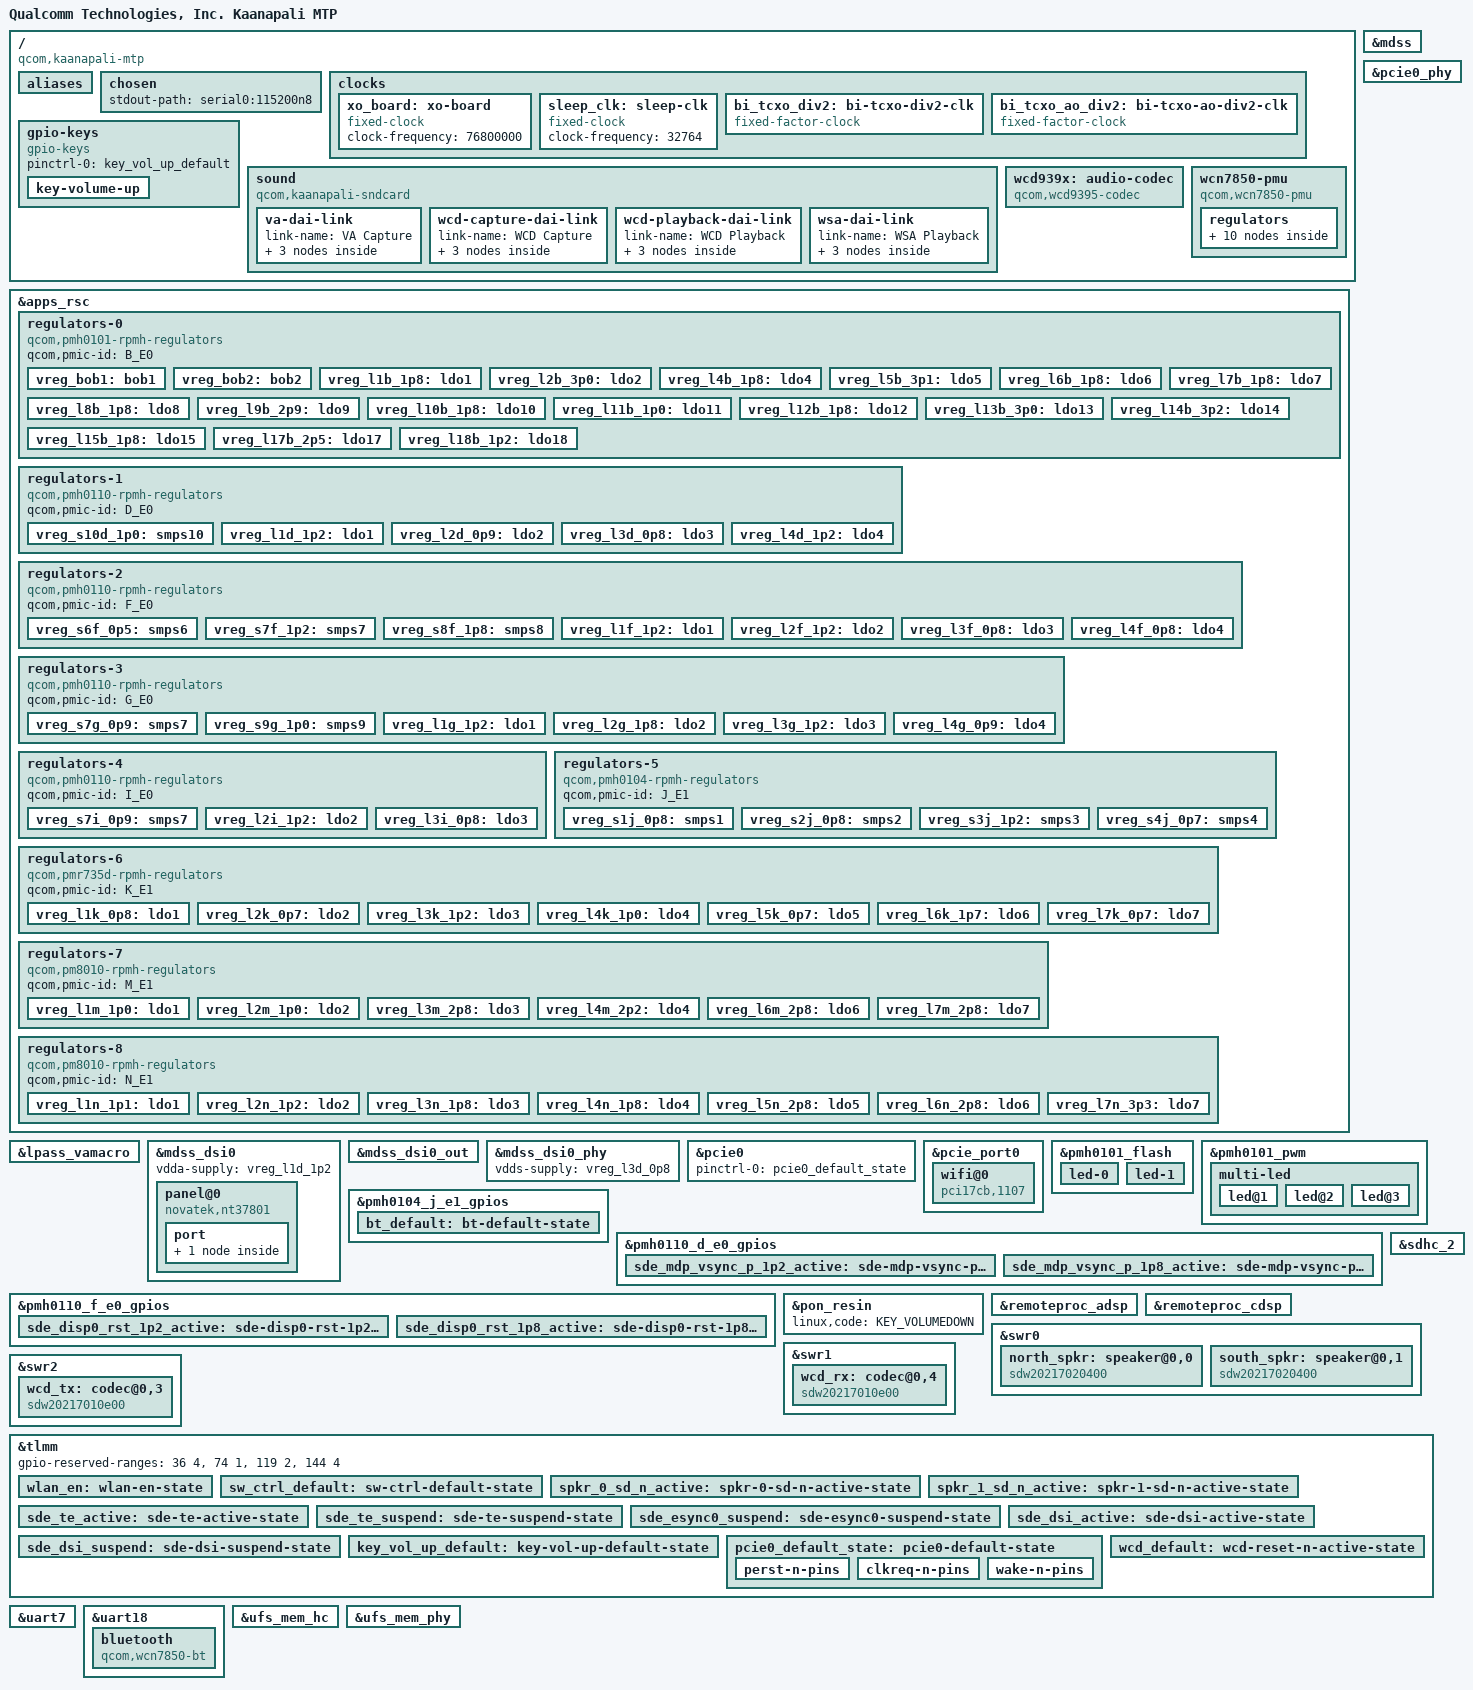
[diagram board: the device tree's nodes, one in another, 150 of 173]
// SPDX-License-Identifier: BSD-3-Clause
/*
 * Copyright (c) Qualcomm Technologies, Inc. and/or its subsidiaries.
 */

/dts-v1/;

#include <dt-bindings/gpio/gpio.h>
#include <dt-bindings/input/linux-event-codes.h>
#include <dt-bindings/leds/common.h>
#include <dt-bindings/regulator/qcom,rpmh-regulator.h>
#include "kaanapali.dtsi"

#include "pm8010-kaanapali.dtsi"     /* SPMI1: SID-12/13   */
#include "pmd8028-kaanapali.dtsi"    /* SPMI1: SID-4       */
#include "pmh0101.dtsi"              /* SPMI0: SID-1       */
#include "pmh0104-kaanapali.dtsi"    /* SPMI1: SID-9       */
#include "pmh0110-kaanapali.dtsi"    /* SPMI0: SID-3/5/6/8 */
#include "pmih0108-kaanapali.dtsi"   /* SPMI1: SID-7       */
#include "pmk8850.dtsi"              /* SPMI0: SID-0       */
#include "pmr735d-kaanapali.dtsi"    /* SPMI1: SID-10      */

/ {
	model = "Qualcomm Technologies, Inc. Kaanapali MTP";
	compatible = "qcom,kaanapali-mtp", "qcom,kaanapali";
	chassis-type = "handset";

	aliases {
		serial0 = &uart7;
		serial1 = &uart18;
	};

	chosen {
		stdout-path = "serial0:115200n8";
	};

	clocks {
		xo_board: xo-board {
			compatible = "fixed-clock";
			clock-frequency = <76800000>;
			#clock-cells = <0>;
		};

		sleep_clk: sleep-clk {
			compatible = "fixed-clock";
			clock-frequency = <32764>;
			#clock-cells = <0>;
		};

		bi_tcxo_div2: bi-tcxo-div2-clk {
			compatible = "fixed-factor-clock";
			#clock-cells = <0>;

			clocks = <&rpmhcc RPMH_CXO_CLK>;
			clock-mult = <1>;
			clock-div = <2>;
		};

		bi_tcxo_ao_div2: bi-tcxo-ao-div2-clk {
			compatible = "fixed-factor-clock";
			#clock-cells = <0>;

			clocks = <&rpmhcc RPMH_CXO_CLK_A>;
			clock-mult = <1>;
			clock-div = <2>;
		};
	};

	gpio-keys {
		compatible = "gpio-keys";

		pinctrl-0 = <&key_vol_up_default>;
		pinctrl-names = "default";

		key-volume-up {
			label = "Volume Up";
			linux,code = <KEY_VOLUMEUP>;
			gpios = <&tlmm 101 GPIO_ACTIVE_LOW>;
			debounce-interval = <15>;
			linux,can-disable;
			wakeup-source;
		};
	};

	sound {
		compatible = "qcom,kaanapali-sndcard", "qcom,sm8450-sndcard";
		model = "Kaanapali-MTP";

		audio-routing = "SpkrLeft IN", "WSA_SPK1 OUT",
				"SpkrRight IN", "WSA_SPK2 OUT",
				"IN1_HPHL", "HPHL_OUT",
				"IN2_HPHR", "HPHR_OUT",
				"AMIC2", "MIC BIAS2",
				"VA DMIC0", "MIC BIAS1",
				"VA DMIC1", "MIC BIAS1",
				"VA DMIC2", "MIC BIAS3",
				"VA DMIC3", "MIC BIAS3",
				"TX SWR_INPUT1", "ADC2_OUTPUT";

		va-dai-link {
			link-name = "VA Capture";

			codec {
				sound-dai = <&lpass_vamacro 0>;
			};

			cpu {
				sound-dai = <&q6apmbedai VA_CODEC_DMA_TX_0>;
			};

			platform {
				sound-dai = <&q6apm>;
			};
		};

		wcd-capture-dai-link {
			link-name = "WCD Capture";

			codec {
				sound-dai = <&wcd939x 1>, <&swr2 0>, <&lpass_txmacro 0>;
			};

			cpu {
				sound-dai = <&q6apmbedai TX_CODEC_DMA_TX_3>;
			};

			platform {
				sound-dai = <&q6apm>;
			};
		};

		wcd-playback-dai-link {
			link-name = "WCD Playback";

			codec {
				sound-dai = <&wcd939x 0>, <&swr1 0>, <&lpass_rxmacro 0>;
			};

			cpu {
				sound-dai = <&q6apmbedai RX_CODEC_DMA_RX_0>;
			};

			platform {
				sound-dai = <&q6apm>;
			};
		};

		wsa-dai-link {
			link-name = "WSA Playback";

			codec {
				sound-dai = <&north_spkr>, <&south_spkr>, <&swr0 0>,
					    <&lpass_wsamacro 0>;
			};

			cpu {
				sound-dai = <&q6apmbedai WSA_CODEC_DMA_RX_0>;
			};

			platform {
				sound-dai = <&q6apm>;
			};
		};
	};

	wcd939x: audio-codec {
		compatible = "qcom,wcd9395-codec", "qcom,wcd9390-codec";

		pinctrl-0 = <&wcd_default>;
		pinctrl-names = "default";

		qcom,micbias1-microvolt = <1800000>;
		qcom,micbias2-microvolt = <1800000>;
		qcom,micbias3-microvolt = <1800000>;
		qcom,micbias4-microvolt = <1800000>;
		qcom,mbhc-buttons-vthreshold-microvolt = <75000 150000 237000 500000
							  500000 500000 500000 500000>;
		qcom,mbhc-headset-vthreshold-microvolt = <1700000>;
		qcom,mbhc-headphone-vthreshold-microvolt = <50000>;
		qcom,rx-device = <&wcd_rx>;
		qcom,tx-device = <&wcd_tx>;

		reset-gpios = <&tlmm 161 GPIO_ACTIVE_LOW>;

		vdd-buck-supply = <&vreg_l15b_1p8>;
		vdd-rxtx-supply = <&vreg_l15b_1p8>;
		vdd-io-supply = <&vreg_l15b_1p8>;
		vdd-mic-bias-supply = <&vreg_bob1>;
		vdd-px-supply = <&vreg_l1g_1p2>;

		#sound-dai-cells = <1>;
	};

	wcn7850-pmu {
		compatible = "qcom,wcn7850-pmu";

		pinctrl-0 = <&bt_default>, <&sw_ctrl_default>, <&wlan_en>;
		pinctrl-names = "default";

		bt-enable-gpios = <&pmh0104_j_e1_gpios 5 GPIO_ACTIVE_HIGH>;
		wlan-enable-gpios = <&tlmm 16 GPIO_ACTIVE_HIGH>;

		vdd-supply = <&vreg_s2j_0p8>;
		vddio-supply = <&vreg_l2g_1p8>;
		vddio1p2-supply = <&vreg_l3g_1p2>;
		vddaon-supply = <&vreg_s7g_0p9>;
		vdddig-supply = <&vreg_s1j_0p8>;
		vddrfa1p2-supply = <&vreg_s7f_1p2>;
		vddrfa1p8-supply = <&vreg_s8f_1p8>;

		clocks = <&rpmhcc RPMH_RF_CLK1>;

		regulators {
			vreg_pmu_rfa_cmn: ldo0 {
				regulator-name = "vreg_pmu_rfa_cmn";
			};

			vreg_pmu_aon_0p59: ldo1 {
				regulator-name = "vreg_pmu_aon_0p59";
			};

			vreg_pmu_wlcx_0p8: ldo2 {
				regulator-name = "vreg_pmu_wlcx_0p8";
			};

			vreg_pmu_wlmx_0p85: ldo3 {
				regulator-name = "vreg_pmu_wlmx_0p85";
			};

			vreg_pmu_btcmx_0p85: ldo4 {
				regulator-name = "vreg_pmu_btcmx_0p85";
			};

			vreg_pmu_rfa_0p8: ldo5 {
				regulator-name = "vreg_pmu_rfa_0p8";
			};

			vreg_pmu_rfa_1p2: ldo6 {
				regulator-name = "vreg_pmu_rfa_1p2";
			};

			vreg_pmu_rfa_1p8: ldo7 {
				regulator-name = "vreg_pmu_rfa_1p8";
			};

			vreg_pmu_pcie_0p9: ldo8 {
				regulator-name = "vreg_pmu_pcie_0p9";
			};

			vreg_pmu_pcie_1p8: ldo9 {
				regulator-name = "vreg_pmu_pcie_1p8";
			};
		};
	};
};

&apps_rsc {
	regulators-0 {
		compatible = "qcom,pmh0101-rpmh-regulators";
		qcom,pmic-id = "B_E0";

		vreg_bob1: bob1 {
			regulator-name = "vreg_bob1";
			regulator-min-microvolt = <3008000>;
			regulator-max-microvolt = <4000000>;
			regulator-initial-mode = <RPMH_REGULATOR_MODE_HPM>;
		};

		vreg_bob2: bob2 {
			regulator-name = "vreg_bob2";
			regulator-min-microvolt = <2704000>;
			regulator-max-microvolt = <3552000>;
			regulator-initial-mode = <RPMH_REGULATOR_MODE_HPM>;
		};

		vreg_l1b_1p8: ldo1 {
			regulator-name = "vreg_l1b_1p8";
			regulator-min-microvolt = <1800000>;
			regulator-max-microvolt = <1800000>;
			regulator-initial-mode = <RPMH_REGULATOR_MODE_AUTO>;
			regulator-allow-set-load;
			regulator-allowed-modes = <RPMH_REGULATOR_MODE_LPM
						   RPMH_REGULATOR_MODE_AUTO>;
		};

		vreg_l2b_3p0: ldo2 {
			regulator-name = "vreg_l2b_3p0";
			regulator-min-microvolt = <3008000>;
			regulator-max-microvolt = <3048000>;
			regulator-initial-mode = <RPMH_REGULATOR_MODE_AUTO>;
			regulator-allow-set-load;
			regulator-allowed-modes = <RPMH_REGULATOR_MODE_LPM
						   RPMH_REGULATOR_MODE_AUTO>;
		};

		vreg_l4b_1p8: ldo4 {
			regulator-name = "vreg_l4b_1p8";
			regulator-min-microvolt = <1800000>;
			regulator-max-microvolt = <1800000>;
			regulator-initial-mode = <RPMH_REGULATOR_MODE_AUTO>;
			regulator-allow-set-load;
			regulator-allowed-modes = <RPMH_REGULATOR_MODE_LPM
						   RPMH_REGULATOR_MODE_AUTO>;
		};

		vreg_l5b_3p1: ldo5 {
			regulator-name = "vreg_l5b_3p1";
			regulator-min-microvolt = <3100000>;
			regulator-max-microvolt = <3148000>;
			regulator-initial-mode = <RPMH_REGULATOR_MODE_AUTO>;
			regulator-allow-set-load;
			regulator-allowed-modes = <RPMH_REGULATOR_MODE_LPM
						   RPMH_REGULATOR_MODE_AUTO>;
		};

		vreg_l6b_1p8: ldo6 {
			regulator-name = "vreg_l6b_1p8";
			regulator-min-microvolt = <1800000>;
			regulator-max-microvolt = <3008000>;
			regulator-initial-mode = <RPMH_REGULATOR_MODE_AUTO>;
			regulator-allow-set-load;
			regulator-allowed-modes = <RPMH_REGULATOR_MODE_LPM
						   RPMH_REGULATOR_MODE_AUTO>;
		};

		vreg_l7b_1p8: ldo7 {
			regulator-name = "vreg_l7b_1p8";
			regulator-min-microvolt = <1800000>;
			regulator-max-microvolt = <3008000>;
			regulator-initial-mode = <RPMH_REGULATOR_MODE_AUTO>;
			regulator-allow-set-load;
			regulator-allowed-modes = <RPMH_REGULATOR_MODE_LPM
						   RPMH_REGULATOR_MODE_AUTO>;
		};

		vreg_l8b_1p8: ldo8 {
			regulator-name = "vreg_l8b_1p8";
			regulator-min-microvolt = <1800000>;
			regulator-max-microvolt = <3008000>;
			regulator-initial-mode = <RPMH_REGULATOR_MODE_AUTO>;
			regulator-allow-set-load;
			regulator-allowed-modes = <RPMH_REGULATOR_MODE_LPM
						   RPMH_REGULATOR_MODE_AUTO>;
		};

		vreg_l9b_2p9: ldo9 {
			regulator-name = "vreg_l9b_2p9";
			regulator-min-microvolt = <2960000>;
			regulator-max-microvolt = <3008000>;
			regulator-initial-mode = <RPMH_REGULATOR_MODE_HPM>;
			regulator-allow-set-load;
			regulator-allowed-modes = <RPMH_REGULATOR_MODE_LPM
						   RPMH_REGULATOR_MODE_HPM>;
		};

		vreg_l10b_1p8: ldo10 {
			regulator-name = "vreg_l10b_1p8";
			regulator-min-microvolt = <1800000>;
			regulator-max-microvolt = <1800000>;
			regulator-initial-mode = <RPMH_REGULATOR_MODE_AUTO>;
			regulator-allow-set-load;
			regulator-allowed-modes = <RPMH_REGULATOR_MODE_LPM
						   RPMH_REGULATOR_MODE_AUTO>;
		};

		vreg_l11b_1p0: ldo11 {
			regulator-name = "vreg_l11b_1p0";
			regulator-min-microvolt = <1000000>;
			regulator-max-microvolt = <1292000>;
			regulator-initial-mode = <RPMH_REGULATOR_MODE_AUTO>;
			regulator-allow-set-load;
			regulator-allowed-modes = <RPMH_REGULATOR_MODE_LPM
						   RPMH_REGULATOR_MODE_AUTO>;
		};

		vreg_l12b_1p8: ldo12 {
			regulator-name = "vreg_l12b_1p8";
			regulator-min-microvolt = <1650000>;
			regulator-max-microvolt = <1800000>;
			regulator-initial-mode = <RPMH_REGULATOR_MODE_AUTO>;
			regulator-allow-set-load;
			regulator-allowed-modes = <RPMH_REGULATOR_MODE_LPM
						   RPMH_REGULATOR_MODE_AUTO>;
		};

		vreg_l13b_3p0: ldo13 {
			regulator-name = "vreg_l13b_3p0";
			regulator-min-microvolt = <3000000>;
			regulator-max-microvolt = <3000000>;
			regulator-initial-mode = <RPMH_REGULATOR_MODE_AUTO>;
			regulator-allow-set-load;
			regulator-allowed-modes = <RPMH_REGULATOR_MODE_LPM
						   RPMH_REGULATOR_MODE_AUTO>;
		};

		vreg_l14b_3p2: ldo14 {
			regulator-name = "vreg_l14b_3p2";
			regulator-min-microvolt = <3200000>;
			regulator-max-microvolt = <3200000>;
			regulator-initial-mode = <RPMH_REGULATOR_MODE_AUTO>;
			regulator-allow-set-load;
			regulator-allowed-modes = <RPMH_REGULATOR_MODE_LPM
						   RPMH_REGULATOR_MODE_AUTO>;
		};

		vreg_l15b_1p8: ldo15 {
			regulator-name = "vreg_l15b_1p8";
			regulator-min-microvolt = <1800000>;
			regulator-max-microvolt = <1800000>;
			regulator-initial-mode = <RPMH_REGULATOR_MODE_AUTO>;
			regulator-allow-set-load;
			regulator-allowed-modes = <RPMH_REGULATOR_MODE_LPM
						   RPMH_REGULATOR_MODE_AUTO>;
		};

		vreg_l17b_2p5: ldo17 {
			regulator-name = "vreg_l17b_2p5";
			regulator-min-microvolt = <2504000>;
			regulator-max-microvolt = <2504000>;
			regulator-initial-mode = <RPMH_REGULATOR_MODE_HPM>;
			regulator-allow-set-load;
			regulator-allowed-modes = <RPMH_REGULATOR_MODE_LPM
						   RPMH_REGULATOR_MODE_HPM>;
		};

		vreg_l18b_1p2: ldo18 {
			regulator-name = "vreg_l18b_1p2";
			regulator-min-microvolt = <1200000>;
			regulator-max-microvolt = <1200000>;
			regulator-initial-mode = <RPMH_REGULATOR_MODE_AUTO>;
			regulator-allow-set-load;
			regulator-allowed-modes = <RPMH_REGULATOR_MODE_LPM
						   RPMH_REGULATOR_MODE_AUTO>;
		};
	};

	regulators-1 {
		compatible = "qcom,pmh0110-rpmh-regulators";
		qcom,pmic-id = "D_E0";

		vreg_s10d_1p0: smps10 {
			regulator-name = "vreg_s10d_1p0";
			regulator-min-microvolt = <1000000>;
			regulator-max-microvolt = <1100000>;
			regulator-initial-mode = <RPMH_REGULATOR_MODE_HPM>;
		};

		vreg_l1d_1p2: ldo1 {
			regulator-name = "vreg_l1d_1p2";
			regulator-min-microvolt = <1200000>;
			regulator-max-microvolt = <1256000>;
			regulator-initial-mode = <RPMH_REGULATOR_MODE_AUTO>;
			regulator-allow-set-load;
			regulator-allowed-modes = <RPMH_REGULATOR_MODE_LPM
						   RPMH_REGULATOR_MODE_AUTO>;
		};

		vreg_l2d_0p9: ldo2 {
			regulator-name = "vreg_l2d_0p9";
			regulator-min-microvolt = <912000>;
			regulator-max-microvolt = <958000>;
			regulator-initial-mode = <RPMH_REGULATOR_MODE_AUTO>;
			regulator-allow-set-load;
			regulator-allowed-modes = <RPMH_REGULATOR_MODE_LPM
						   RPMH_REGULATOR_MODE_AUTO>;
		};

		vreg_l3d_0p8: ldo3 {
			regulator-name = "vreg_l3d_0p8";
			regulator-min-microvolt = <880000>;
			regulator-max-microvolt = <880000>;
			regulator-initial-mode = <RPMH_REGULATOR_MODE_AUTO>;
			regulator-allow-set-load;
			regulator-allowed-modes = <RPMH_REGULATOR_MODE_LPM
						   RPMH_REGULATOR_MODE_AUTO>;
		};

		vreg_l4d_1p2: ldo4 {
			regulator-name = "vreg_l4d_1p2";
			regulator-min-microvolt = <1200000>;
			regulator-max-microvolt = <1200000>;
			regulator-initial-mode = <RPMH_REGULATOR_MODE_AUTO>;
			regulator-allow-set-load;
			regulator-allowed-modes = <RPMH_REGULATOR_MODE_LPM
						   RPMH_REGULATOR_MODE_AUTO>;
		};
	};

	regulators-2 {
		compatible = "qcom,pmh0110-rpmh-regulators";
		qcom,pmic-id = "F_E0";

		vreg_s6f_0p5: smps6 {
			regulator-name = "vreg_s6f_0p5";
			regulator-min-microvolt = <300000>;
			regulator-max-microvolt = <570000>;
			regulator-initial-mode = <RPMH_REGULATOR_MODE_HPM>;
		};

		vreg_s7f_1p2: smps7 {
			regulator-name = "vreg_s7f_1p2";
			regulator-min-microvolt = <1224000>;
			regulator-max-microvolt = <1372000>;
			regulator-initial-mode = <RPMH_REGULATOR_MODE_HPM>;
		};

		vreg_s8f_1p8: smps8 {
			regulator-name = "vreg_s8f_1p8";
			regulator-min-microvolt = <1800000>;
			regulator-max-microvolt = <2000000>;
			regulator-initial-mode = <RPMH_REGULATOR_MODE_HPM>;
		};

		vreg_l1f_1p2: ldo1 {
			regulator-name = "vreg_l1f_1p2";
			regulator-min-microvolt = <1200000>;
			regulator-max-microvolt = <1200000>;
			regulator-initial-mode = <RPMH_REGULATOR_MODE_AUTO>;
			regulator-allow-set-load;
			regulator-allowed-modes = <RPMH_REGULATOR_MODE_LPM
						   RPMH_REGULATOR_MODE_AUTO>;
		};

		vreg_l2f_1p2: ldo2 {
			regulator-name = "vreg_l2f_1p2";
			regulator-min-microvolt = <1200000>;
			regulator-max-microvolt = <1200000>;
			regulator-initial-mode = <RPMH_REGULATOR_MODE_AUTO>;
			regulator-allow-set-load;
			regulator-allowed-modes = <RPMH_REGULATOR_MODE_LPM
						   RPMH_REGULATOR_MODE_AUTO>;
		};

		vreg_l3f_0p8: ldo3 {
			regulator-name = "vreg_l3f_0p8";
			regulator-min-microvolt = <880000>;
			regulator-max-microvolt = <936000>;
			regulator-initial-mode = <RPMH_REGULATOR_MODE_AUTO>;
			regulator-allow-set-load;
			regulator-allowed-modes = <RPMH_REGULATOR_MODE_LPM
						   RPMH_REGULATOR_MODE_AUTO>;
		};

		vreg_l4f_0p8: ldo4 {
			regulator-name = "vreg_l4f_0p8";
			regulator-min-microvolt = <880000>;
			regulator-max-microvolt = <912000>;
			regulator-initial-mode = <RPMH_REGULATOR_MODE_AUTO>;
			regulator-allow-set-load;
			regulator-allowed-modes = <RPMH_REGULATOR_MODE_LPM
						   RPMH_REGULATOR_MODE_AUTO>;
		};
	};

	regulators-3 {
		compatible = "qcom,pmh0110-rpmh-regulators";
		qcom,pmic-id = "G_E0";

		vreg_s7g_0p9: smps7 {
			regulator-name = "vreg_s7g_0p9";
			regulator-min-microvolt = <880000>;
			regulator-max-microvolt = <1100000>;
			regulator-initial-mode = <RPMH_REGULATOR_MODE_HPM>;
		};

		vreg_s9g_1p0: smps9 {
			regulator-name = "vreg_s9g_1p0";
			regulator-min-microvolt = <1000000>;
			regulator-max-microvolt = <1100000>;
			regulator-initial-mode = <RPMH_REGULATOR_MODE_HPM>;
		};

		vreg_l1g_1p2: ldo1 {
			regulator-name = "vreg_l1g_1p2";
			regulator-min-microvolt = <1200000>;
			regulator-max-microvolt = <1200000>;
			regulator-initial-mode = <RPMH_REGULATOR_MODE_AUTO>;
			regulator-allow-set-load;
			regulator-allowed-modes = <RPMH_REGULATOR_MODE_LPM
						   RPMH_REGULATOR_MODE_AUTO>;
		};

		vreg_l2g_1p8: ldo2 {
			regulator-name = "vreg_l2g_1p8";
			regulator-min-microvolt = <1800000>;
			regulator-max-microvolt = <1800000>;
			regulator-initial-mode = <RPMH_REGULATOR_MODE_AUTO>;
			regulator-allow-set-load;
			regulator-allowed-modes = <RPMH_REGULATOR_MODE_LPM
						   RPMH_REGULATOR_MODE_AUTO>;
		};

		vreg_l3g_1p2: ldo3 {
			regulator-name = "vreg_l3g_1p2";
			regulator-min-microvolt = <1200000>;
			regulator-max-microvolt = <1200000>;
			regulator-initial-mode = <RPMH_REGULATOR_MODE_AUTO>;
			regulator-allow-set-load;
			regulator-allowed-modes = <RPMH_REGULATOR_MODE_LPM
						   RPMH_REGULATOR_MODE_AUTO>;
		};

		vreg_l4g_0p9: ldo4 {
			regulator-name = "vreg_l4g_0p9";
			regulator-min-microvolt = <880000>;
			regulator-max-microvolt = <920000>;
			regulator-initial-mode = <RPMH_REGULATOR_MODE_AUTO>;
			regulator-allow-set-load;
			regulator-allowed-modes = <RPMH_REGULATOR_MODE_LPM
						   RPMH_REGULATOR_MODE_AUTO>;
		};
	};

	regulators-4 {
		compatible = "qcom,pmh0110-rpmh-regulators";
		qcom,pmic-id = "I_E0";

		vreg_s7i_0p9: smps7 {
			regulator-name = "vreg_s7i_0p9";
			regulator-min-microvolt = <900000>;
			regulator-max-microvolt = <972000>;
			regulator-initial-mode = <RPMH_REGULATOR_MODE_HPM>;
		};

		vreg_l2i_1p2: ldo2 {
			regulator-name = "vreg_l2i_1p2";
			regulator-min-microvolt = <1200000>;
			regulator-max-microvolt = <1200000>;
			regulator-initial-mode = <RPMH_REGULATOR_MODE_AUTO>;
			regulator-allow-set-load;
			regulator-allowed-modes = <RPMH_REGULATOR_MODE_LPM
						   RPMH_REGULATOR_MODE_AUTO>;
		};

		vreg_l3i_0p8: ldo3 {
			regulator-name = "vreg_l3i_0p8";
			regulator-min-microvolt = <880000>;
			regulator-max-microvolt = <920000>;
			regulator-initial-mode = <RPMH_REGULATOR_MODE_AUTO>;
			regulator-allow-set-load;
			regulator-allowed-modes = <RPMH_REGULATOR_MODE_LPM
						   RPMH_REGULATOR_MODE_AUTO>;
		};
	};

	regulators-5 {
		compatible = "qcom,pmh0104-rpmh-regulators";
		qcom,pmic-id = "J_E1";

		vreg_s1j_0p8: smps1 {
			regulator-name = "vreg_s1j_0p8";
			regulator-min-microvolt = <400000>;
			regulator-max-microvolt = <1000000>;
			regulator-initial-mode = <RPMH_REGULATOR_MODE_HPM>;
		};

		vreg_s2j_0p8: smps2 {
			regulator-name = "vreg_s2j_0p8";
			regulator-min-microvolt = <500000>;
			regulator-max-microvolt = <1100000>;
			regulator-initial-mode = <RPMH_REGULATOR_MODE_HPM>;
		};

		vreg_s3j_1p2: smps3 {
			regulator-name = "vreg_s3j_1p2";
			regulator-min-microvolt = <1200000>;
			regulator-max-microvolt = <1300000>;
			regulator-initial-mode = <RPMH_REGULATOR_MODE_HPM>;
		};

		vreg_s4j_0p7: smps4 {
			regulator-name = "vreg_s4j_0p7";
			regulator-min-microvolt = <300000>;
			regulator-max-microvolt = <1000000>;
			regulator-initial-mode = <RPMH_REGULATOR_MODE_HPM>;
		};
	};

	regulators-6 {
		compatible = "qcom,pmr735d-rpmh-regulators";
		qcom,pmic-id = "K_E1";

		vreg_l1k_0p8: ldo1 {
			regulator-name = "vreg_l1k_0p8";
			regulator-min-microvolt = <300000>;
			regulator-max-microvolt = <1100000>;
			regulator-initial-mode = <RPMH_REGULATOR_MODE_HPM>;
			regulator-allow-set-load;
			regulator-allowed-modes = <RPMH_REGULATOR_MODE_LPM
						   RPMH_REGULATOR_MODE_HPM>;
		};

		vreg_l2k_0p7: ldo2 {
			regulator-name = "vreg_l2k_0p7";
			regulator-min-microvolt = <700000>;
			regulator-max-microvolt = <1000000>;
			regulator-initial-mode = <RPMH_REGULATOR_MODE_HPM>;
			regulator-allow-set-load;
			regulator-allowed-modes = <RPMH_REGULATOR_MODE_LPM
						   RPMH_REGULATOR_MODE_HPM>;
		};

		vreg_l3k_1p2: ldo3 {
			regulator-name = "vreg_l3k_1p2";
			regulator-min-microvolt = <1200000>;
			regulator-max-microvolt = <1200000>;
			regulator-initial-mode = <RPMH_REGULATOR_MODE_HPM>;
			regulator-allow-set-load;
			regulator-allowed-modes = <RPMH_REGULATOR_MODE_LPM
						   RPMH_REGULATOR_MODE_HPM>;
		};

		vreg_l4k_1p0: ldo4 {
			regulator-name = "vreg_l4k_1p0";
			regulator-min-microvolt = <1000000>;
			regulator-max-microvolt = <1200000>;
			regulator-initial-mode = <RPMH_REGULATOR_MODE_HPM>;
			regulator-allow-set-load;
			regulator-allowed-modes = <RPMH_REGULATOR_MODE_LPM
						   RPMH_REGULATOR_MODE_HPM>;
		};

		vreg_l5k_0p7: ldo5 {
			regulator-name = "vreg_l5k_0p7";
			regulator-min-microvolt = <700000>;
			regulator-max-microvolt = <1000000>;
			regulator-initial-mode = <RPMH_REGULATOR_MODE_HPM>;
			regulator-allow-set-load;
			regulator-allowed-modes = <RPMH_REGULATOR_MODE_LPM
						   RPMH_REGULATOR_MODE_HPM>;
		};

		vreg_l6k_1p7: ldo6 {
			regulator-name = "vreg_l6k_1p7";
			regulator-min-microvolt = <1700000>;
			regulator-max-microvolt = <2000000>;
			regulator-initial-mode = <RPMH_REGULATOR_MODE_HPM>;
			regulator-allow-set-load;
			regulator-allowed-modes = <RPMH_REGULATOR_MODE_LPM
						   RPMH_REGULATOR_MODE_HPM>;
		};

		vreg_l7k_0p7: ldo7 {
			regulator-name = "vreg_l7k_0p7";
			regulator-min-microvolt = <700000>;
			regulator-max-microvolt = <848000>;
			regulator-initial-mode = <RPMH_REGULATOR_MODE_HPM>;
			regulator-allow-set-load;
			regulator-allowed-modes = <RPMH_REGULATOR_MODE_LPM
						   RPMH_REGULATOR_MODE_HPM>;
		};
	};

	regulators-7 {
		compatible = "qcom,pm8010-rpmh-regulators";
		qcom,pmic-id = "M_E1";

		vreg_l1m_1p0: ldo1 {
			regulator-name = "vreg_l1m_1p0";
			regulator-min-microvolt = <1000000>;
			regulator-max-microvolt = <1100000>;
			regulator-initial-mode = <RPMH_REGULATOR_MODE_HPM>;
			regulator-allow-set-load;
			regulator-allowed-modes = <RPMH_REGULATOR_MODE_LPM
						   RPMH_REGULATOR_MODE_HPM>;
		};

		vreg_l2m_1p0: ldo2 {
			regulator-name = "vreg_l2m_1p0";
			regulator-min-microvolt = <1096000>;
			regulator-max-microvolt = <1104000>;
			regulator-initial-mode = <RPMH_REGULATOR_MODE_HPM>;
			regulator-allow-set-load;
			regulator-allowed-modes = <RPMH_REGULATOR_MODE_LPM
						   RPMH_REGULATOR_MODE_HPM>;
		};

		vreg_l3m_2p8: ldo3 {
			regulator-name = "vreg_l3m_2p8";
			regulator-min-microvolt = <2800000>;
			regulator-max-microvolt = <2900000>;
			regulator-initial-mode = <RPMH_REGULATOR_MODE_HPM>;
		};

		vreg_l4m_2p2: ldo4 {
			regulator-name = "vreg_l4m_2p2";
			regulator-min-microvolt = <2200000>;
			regulator-max-microvolt = <2200000>;
			regulator-initial-mode = <RPMH_REGULATOR_MODE_HPM>;
		};

		vreg_l6m_2p8: ldo6 {
			regulator-name = "vreg_l6m_2p8";
			regulator-min-microvolt = <2800000>;
			regulator-max-microvolt = <2800000>;
			regulator-initial-mode = <RPMH_REGULATOR_MODE_HPM>;
		};

		vreg_l7m_2p8: ldo7 {
			regulator-name = "vreg_l7m_2p8";
			regulator-min-microvolt = <2800000>;
			regulator-max-microvolt = <2800000>;
			regulator-initial-mode = <RPMH_REGULATOR_MODE_HPM>;
		};
	};

	regulators-8 {
		compatible = "qcom,pm8010-rpmh-regulators";
		qcom,pmic-id = "N_E1";

		vreg_l1n_1p1: ldo1 {
			regulator-name = "vreg_l1n_1p1";
			regulator-min-microvolt = <1096000>;
			regulator-max-microvolt = <1104000>;
			regulator-initial-mode = <RPMH_REGULATOR_MODE_HPM>;
			regulator-allow-set-load;
			regulator-allowed-modes = <RPMH_REGULATOR_MODE_LPM
						   RPMH_REGULATOR_MODE_HPM>;
		};

		vreg_l2n_1p2: ldo2 {
			regulator-name = "vreg_l2n_1p2";
			regulator-min-microvolt = <1200000>;
			regulator-max-microvolt = <1200000>;
			regulator-initial-mode = <RPMH_REGULATOR_MODE_HPM>;
			regulator-allow-set-load;
			regulator-allowed-modes = <RPMH_REGULATOR_MODE_LPM
						   RPMH_REGULATOR_MODE_HPM>;
		};

		vreg_l3n_1p8: ldo3 {
			regulator-name = "vreg_l3n_1p8";
			regulator-min-microvolt = <1800000>;
			regulator-max-microvolt = <1800000>;
			regulator-initial-mode = <RPMH_REGULATOR_MODE_HPM>;
		};

		vreg_l4n_1p8: ldo4 {
			regulator-name = "vreg_l4n_1p8";
			regulator-min-microvolt = <1800000>;
			regulator-max-microvolt = <1800000>;
			regulator-initial-mode = <RPMH_REGULATOR_MODE_HPM>;
		};

		vreg_l5n_2p8: ldo5 {
			regulator-name = "vreg_l5n_2p8";
			regulator-min-microvolt = <2800000>;
			regulator-max-microvolt = <2800000>;
			regulator-initial-mode = <RPMH_REGULATOR_MODE_HPM>;
		};

		vreg_l6n_2p8: ldo6 {
			regulator-name = "vreg_l6n_2p8";
			regulator-min-microvolt = <2800000>;
			regulator-max-microvolt = <2800000>;
			regulator-initial-mode = <RPMH_REGULATOR_MODE_HPM>;
		};

		vreg_l7n_3p3: ldo7 {
			regulator-name = "vreg_l7n_3p3";
			regulator-min-microvolt = <3304000>;
			regulator-max-microvolt = <3304000>;
			regulator-initial-mode = <RPMH_REGULATOR_MODE_HPM>;
		};
	};
};

&lpass_vamacro {
	pinctrl-0 = <&dmic01_default>, <&dmic23_default>;
	pinctrl-names = "default";

	vdd-micb-supply = <&vreg_l10b_1p8>;
	qcom,dmic-sample-rate = <4800000>;
};

&mdss {
	status = "okay";
};

&mdss_dsi0 {
	vdda-supply = <&vreg_l1d_1p2>;
	status = "okay";

	panel@0 {
		compatible = "novatek,nt37801";
		reg = <0>;

		pinctrl-0 = <&sde_dsi_active &sde_te_active &sde_esync0_suspend
			     &sde_mdp_vsync_p_1p2_active &sde_mdp_vsync_p_1p8_active
			     &sde_disp0_rst_1p2_active &sde_disp0_rst_1p8_active>;
		pinctrl-1 = <&sde_dsi_suspend &sde_te_suspend &sde_esync0_suspend
			     &sde_mdp_vsync_p_1p2_active &sde_mdp_vsync_p_1p8_active
			     &sde_disp0_rst_1p2_active &sde_disp0_rst_1p8_active>;
		pinctrl-names = "default", "sleep";

		vci-supply = <&vreg_l13b_3p0>;
		vdd-supply = <&vreg_l11b_1p0>;
		vddio-supply = <&vreg_l12b_1p8>;

		reset-gpios = <&tlmm 98 GPIO_ACTIVE_LOW>;

		port {
			panel0_in: endpoint {
				remote-endpoint = <&mdss_dsi0_out>;
			};
		};
	};
};

&mdss_dsi0_out {
	remote-endpoint = <&panel0_in>;
	data-lanes = <0 1 2 3>;
};

&mdss_dsi0_phy {
	vdds-supply = <&vreg_l3d_0p8>;

	status = "okay";
};

&pcie0 {
	pinctrl-0 = <&pcie0_default_state>;
	pinctrl-names = "default";

	status = "okay";
};

&pcie0_phy {
	vdda-phy-supply = <&vreg_l3i_0p8>;
	vdda-pll-supply = <&vreg_l1d_1p2>;

	status = "okay";
};

&pcie_port0 {
	wake-gpios = <&tlmm 104 GPIO_ACTIVE_HIGH>;
	reset-gpios = <&tlmm 102 GPIO_ACTIVE_LOW>;

	wifi@0 {
		compatible = "pci17cb,1107";
		reg = <0x10000 0x0 0x0 0x0 0x0>;

		vddrfacmn-supply = <&vreg_pmu_rfa_cmn>;
		vddaon-supply = <&vreg_pmu_aon_0p59>;
		vddwlcx-supply = <&vreg_pmu_wlcx_0p8>;
		vddwlmx-supply = <&vreg_pmu_wlmx_0p85>;
		vddrfa0p8-supply = <&vreg_pmu_rfa_0p8>;
		vddrfa1p2-supply = <&vreg_pmu_rfa_1p2>;
		vddrfa1p8-supply = <&vreg_pmu_rfa_1p8>;
		vddpcie0p9-supply = <&vreg_pmu_pcie_0p9>;
		vddpcie1p8-supply = <&vreg_pmu_pcie_1p8>;
	};
};

&pmh0101_flash {
	status = "okay";

	led-0 {
		function = LED_FUNCTION_FLASH;
		function-enumerator = <0>;
		color = <LED_COLOR_ID_YELLOW>;
		led-sources = <1>, <4>;
		led-max-microamp = <500000>;
		flash-max-microamp = <2000000>;
		flash-max-timeout-us = <1280000>;
	};

	led-1 {
		function = LED_FUNCTION_FLASH;
		function-enumerator = <1>;
		color = <LED_COLOR_ID_WHITE>;
		led-sources = <2>, <3>;
		led-max-microamp = <500000>;
		flash-max-microamp = <2000000>;
		flash-max-timeout-us = <1280000>;
	};
};

&pmh0101_pwm {
	status = "okay";

	multi-led {
		color = <LED_COLOR_ID_RGB>;
		function = LED_FUNCTION_STATUS;

		#address-cells = <1>;
		#size-cells = <0>;

		led@1 {
			reg = <1>;
			color = <LED_COLOR_ID_RED>;
		};

		led@2 {
			reg = <2>;
			color = <LED_COLOR_ID_GREEN>;
		};

		led@3 {
			reg = <3>;
			color = <LED_COLOR_ID_BLUE>;
		};
	};
};

&pmh0104_j_e1_gpios {
	bt_default: bt-default-state {
		pins = "gpio5";
		function = "normal";
		input-disable;
		output-enable;
		output-low;
		bias-disable;
		power-source = <1>;
	};
};

&pmh0110_d_e0_gpios {
	sde_mdp_vsync_p_1p2_active: sde-mdp-vsync-p-1p2-active-state {
		pins = "gpio9";
		function = "paired";
		input-disable;
		output-enable;
		power-source = <2>; /* 1.2v */
	};

	sde_mdp_vsync_p_1p8_active: sde-mdp-vsync-p-1p8-active-state {
		pins = "gpio10";
		function = "paired";
		input-enable;
		output-disable;
		power-source = <1>; /* 1.8v */
	};
};

&pmh0110_f_e0_gpios {
	sde_disp0_rst_1p2_active: sde-disp0-rst-1p2-active-state {
		pins = "gpio9";
		function = "paired";
		input-enable;
		output-disable;
		power-source = <2>; /* 1.2v */
	};

	sde_disp0_rst_1p8_active: sde-disp0-rst-1p8-active-state {
		pins = "gpio10";
		function = "paired";
		input-disable;
		output-enable;
		power-source = <1>; /* 1.8v */
	};
};

&pon_resin {
	linux,code = <KEY_VOLUMEDOWN>;

	status = "okay";
};

&remoteproc_adsp {
	firmware-name = "qcom/kaanapali/adsp.mbn",
			"qcom/kaanapali/adsp_dtb.mbn";

	status = "okay";
};

&remoteproc_cdsp {
	firmware-name = "qcom/kaanapali/cdsp.mbn",
			"qcom/kaanapali/cdsp_dtb.mbn";

	status = "okay";
};

&sdhc_2 {
	cd-gpios = <&tlmm 55 GPIO_ACTIVE_LOW>;

	vmmc-supply = <&vreg_l9b_2p9>;
	vqmmc-supply = <&vreg_l8b_1p8>;

	bus-width = <4>;
	no-sdio;
	no-mmc;

	pinctrl-0 = <&sdc2_default>;
	pinctrl-1 = <&sdc2_sleep>;
	pinctrl-names = "default", "sleep";

	status = "okay";
};

&swr0 {
	status = "okay";

	/* WSA8845, Speaker North */
	north_spkr: speaker@0,0 {
		compatible = "sdw20217020400";
		reg = <0 0>;
		pinctrl-0 = <&spkr_0_sd_n_active>;
		pinctrl-names = "default";
		powerdown-gpios = <&tlmm 76 GPIO_ACTIVE_LOW>;
		#sound-dai-cells = <0>;
		sound-name-prefix = "SpkrLeft";
		vdd-1p8-supply = <&vreg_l15b_1p8>;
		vdd-io-supply = <&vreg_l2i_1p2>;

		/*
		 * WSA8845 Port 1 (DAC)     <=> SWR0 Port 1 (SPKR_L)
		 * WSA8845 Port 2 (COMP)    <=> SWR0 Port 2 (SPKR_L_COMP)
		 * WSA8845 Port 3 (BOOST)   <=> SWR0 Port 3 (SPKR_L_BOOST)
		 * WSA8845 Port 4 (PBR)     <=> SWR0 Port 7 (PBR)
		 * WSA8845 Port 5 (VISENSE) <=> SWR0 Port 10 (SPKR_L_VI)
		 * WSA8845 Port 6 (CPS)     <=> SWR0 Port 13 (CPS)
		 */
		qcom,port-mapping = <1 2 3 7 10 13>;
	};

	/* WSA8845, Speaker South */
	south_spkr: speaker@0,1 {
		compatible = "sdw20217020400";
		reg = <0 1>;
		pinctrl-0 = <&spkr_1_sd_n_active>;
		pinctrl-names = "default";
		powerdown-gpios = <&tlmm 77 GPIO_ACTIVE_LOW>;
		#sound-dai-cells = <0>;
		sound-name-prefix = "SpkrRight";
		vdd-1p8-supply = <&vreg_l15b_1p8>;
		vdd-io-supply = <&vreg_l2i_1p2>;

		/*
		 * WSA8845 Port 1 (DAC)     <=> SWR0 Port 4 (SPKR_R)
		 * WSA8845 Port 2 (COMP)    <=> SWR0 Port 5 (SPKR_R_COMP)
		 * WSA8845 Port 3 (BOOST)   <=> SWR0 Port 6 (SPKR_R_BOOST)
		 * WSA8845 Port 4 (PBR)     <=> SWR0 Port 7 (PBR)
		 * WSA8845 Port 5 (VISENSE) <=> SWR0 Port 11 (SPKR_R_VI)
		 * WSA8845 Port 6 (CPS)     <=> SWR0 Port 13 (CPS)
		 */
		qcom,port-mapping = <4 5 6 7 11 13>;
	};
};

&swr1 {
	status = "okay";

	/* WCD9395 RX */
	wcd_rx: codec@0,4 {
		compatible = "sdw20217010e00";
		reg = <0 4>;

		/*
		 * WCD9395 RX Port 1 (HPH_L/R)      <=> SWR1 Port 1 (HPH_L/R)
		 * WCD9395 RX Port 2 (CLSH)         <=> SWR1 Port 2 (CLSH)
		 * WCD9395 RX Port 3 (COMP_L/R)     <=> SWR1 Port 3 (COMP_L/R)
		 * WCD9395 RX Port 4 (LO)           <=> SWR1 Port 4 (LO)
		 * WCD9395 RX Port 5 (DSD_L/R)      <=> SWR1 Port 5 (DSD_L/R)
		 * WCD9395 RX Port 6 (HIFI_PCM_L/R) <=> SWR1 Port 9 (HIFI_PCM_L/R)
		 */
		qcom,rx-port-mapping = <1 2 3 4 5 9>;
	};
};

&swr2 {
	status = "okay";

	/* WCD9395 TX */
	wcd_tx: codec@0,3 {
		compatible = "sdw20217010e00";
		reg = <0 3>;

		/*
		 * WCD9395 TX Port 1 (ADC1,2,3,4)         <=> SWR2 Port 2 (TX SWR_INPUT 0,1,2,3)
		 * WCD9395 TX Port 2 (ADC3,4 & DMIC0,1)   <=> SWR2 Port 2 (TX SWR_INPUT 0,1,2,3)
		 * WCD9395 TX Port 3 (DMIC0,1,2,3 & MBHC) <=> SWR2 Port 3 (TX SWR_INPUT 4,5,6,7)
		 * WCD9395 TX Port 4 (DMIC4,5,6,7)        <=> SWR2 Port 4 (TX SWR_INPUT 8,9,10,11)
		 */
		qcom,tx-port-mapping = <2 2 3 4>;
	};
};

&tlmm {
	gpio-reserved-ranges = <36 4>, /* NFC eSE SPI */
			       <74 1>, /* eSE */
			       <119 2>, /* SoCCP */
			       <144 4>; /* CXM UART */

	wlan_en: wlan-en-state {
		pins = "gpio16";
		function = "gpio";
		drive-strength = <8>;
		bias-pull-down;
	};

	sw_ctrl_default: sw-ctrl-default-state {
		pins = "gpio18";
		function = "gpio";
		bias-pull-down;
	};

	spkr_0_sd_n_active: spkr-0-sd-n-active-state {
		pins = "gpio76";
		function = "gpio";
		drive-strength = <16>;
		bias-disable;
	};

	spkr_1_sd_n_active: spkr-1-sd-n-active-state {
		pins = "gpio77";
		function = "gpio";
		drive-strength = <16>;
		bias-disable;
	};

	sde_te_active: sde-te-active-state {
		pins = "gpio86";
		function = "mdp_vsync";
		drive-strength = <2>;
		bias-pull-down;
	};

	sde_te_suspend: sde-te-suspend-state {
		pins = "gpio86";
		function = "mdp_vsync";
		drive-strength = <2>;
		bias-pull-down;
	};

	sde_esync0_suspend: sde-esync0-suspend-state {
		pins = "gpio88";
		function = "mdp_esync0_out";
		drive-strength = <2>;
		bias-pull-down;
	};

	sde_dsi_active: sde-dsi-active-state {
		pins = "gpio98";
		function = "gpio";
		drive-strength = <8>;
		bias-disable;
	};

	sde_dsi_suspend: sde-dsi-suspend-state {
		pins = "gpio98";
		function = "gpio";
		drive-strength = <2>;
		bias-pull-down;
	};

	key_vol_up_default: key-vol-up-default-state {
		pins = "gpio101";
		function = "gpio";
		output-disable;
		bias-pull-up;
	};

	pcie0_default_state: pcie0-default-state {
		perst-n-pins {
			pins = "gpio102";
			function = "gpio";
			drive-strength = <2>;
			bias-disable;
		};

		clkreq-n-pins {
			pins = "gpio103";
			function = "pcie0_clk_req_n";
			drive-strength = <2>;
			bias-pull-up;
		};

		wake-n-pins {
			pins = "gpio104";
			function = "gpio";
			drive-strength = <2>;
			bias-pull-up;
		};
	};

	wcd_default: wcd-reset-n-active-state {
		pins = "gpio161";
		function = "gpio";
		drive-strength = <16>;
		bias-disable;
	};
};

&uart7 {
	status = "okay";
};

&uart18 {
	status = "okay";

	bluetooth {
		compatible = "qcom,wcn7850-bt";

		vddrfacmn-supply = <&vreg_pmu_rfa_cmn>;
		vddaon-supply = <&vreg_pmu_aon_0p59>;
		vddwlcx-supply = <&vreg_pmu_wlcx_0p8>;
		vddwlmx-supply = <&vreg_pmu_wlmx_0p85>;
		vddrfa0p8-supply = <&vreg_pmu_rfa_0p8>;
		vddrfa1p2-supply = <&vreg_pmu_rfa_1p2>;
		vddrfa1p8-supply = <&vreg_pmu_rfa_1p8>;

		max-speed = <3200000>;
	};
};

&ufs_mem_hc {
	reset-gpios = <&tlmm 217 GPIO_ACTIVE_LOW>;

	vcc-supply = <&vreg_l17b_2p5>;
	vcc-max-microamp = <1200000>;
	vccq-supply = <&vreg_l4d_1p2>;
	vccq-max-microamp = <1200000>;

	status = "okay";
};

&ufs_mem_phy {
	vdda-phy-supply = <&vreg_l4g_0p9>;
	vdda-pll-supply = <&vreg_l1d_1p2>;

	status = "okay";
};
